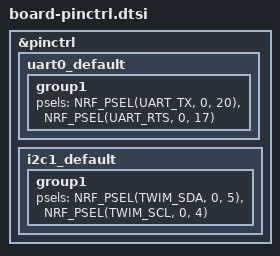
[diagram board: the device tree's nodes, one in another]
&pinctrl {
  uart0_default: uart0_default {
    group1 {
      psels = <NRF_PSEL(UART_TX, 0, 20)>,
              <NRF_PSEL(UART_RTS, 0, 17)>;
    };
  };


  i2c1_default: i2c1_default {
    group1 {
      psels = <NRF_PSEL(TWIM_SDA, 0, 5)>,
              <NRF_PSEL(TWIM_SCL, 0, 4)>;
    };
  };
};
